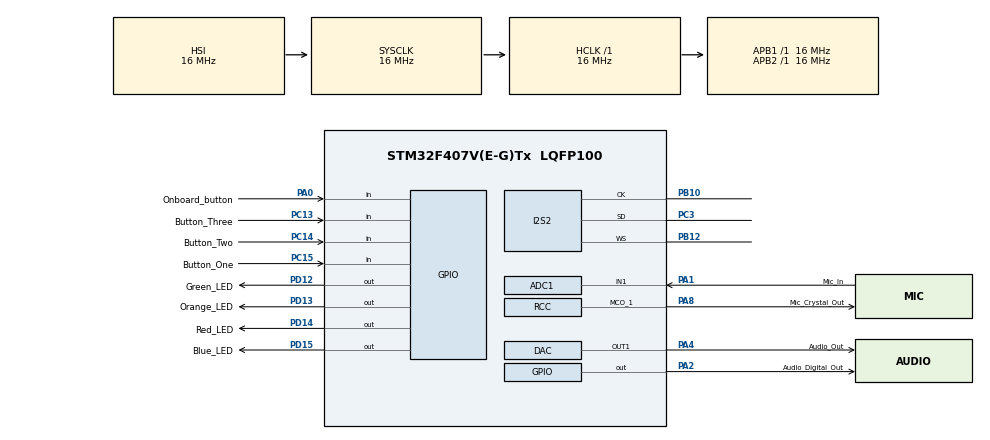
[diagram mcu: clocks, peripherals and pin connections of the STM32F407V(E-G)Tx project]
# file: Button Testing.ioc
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ADC1.Channel-0\#ChannelRegularConversion=ADC_CHANNEL_1
ADC1.NbrOfConversionFlag=1
ADC1.Rank-0\#ChannelRegularConversion=1
ADC1.SamplingTime-0\#ChannelRegularConversion=ADC_SAMPLETIME_3CYCLES
ADC1.master=1
I2S2.ErrorAudioFreq=0.0 %
I2S2.FullDuplexMode=I2S_FULLDUPLEXMODE_DISABLE
I2S2.Instance=SPI$Index
I2S2.RealAudioFreq=8.0 KHz
I2S2.VirtualMode=I2S_MODE_MASTER
Mcu.Family=STM32F4
Mcu.Name=STM32F407V(E-G)Tx
Mcu.Package=LQFP100
NVIC.PriorityGroup=NVIC_PRIORITYGROUP_4
PA0-WKUP.GPIO_Label=Onboard_button
PA0-WKUP.Signal=GPIO_Input
PA1.GPIO_Label=Mic_In
PA1.Signal=ADCx_IN1
PA2.GPIO_Label=Audio_Digital_Out
PA2.Signal=GPIO_Output
PA4.GPIO_Label=Audio_Out
PA4.Signal=COMP_DAC1_group
PA8.GPIO_Label=Mic_Crystal_Out
PA8.Mode=Clock-out-1
PA8.Signal=RCC_MCO_1
PB10.Mode=Half_Duplex_Master
PB10.Signal=I2S2_CK
PB12.Mode=Half_Duplex_Master
PB12.Signal=I2S2_WS
PC13-ANTI_TAMP.GPIO_Label=Button_Three
PC13-ANTI_TAMP.GPIO_PuPd=GPIO_PULLDOWN
PC13-ANTI_TAMP.Signal=GPIO_Input
PC14-OSC32_IN.GPIO_Label=Button_Two
PC14-OSC32_IN.GPIO_PuPd=GPIO_PULLDOWN
PC14-OSC32_IN.Signal=GPIO_Input
PC15-OSC32_OUT.GPIO_Label=Button_One
PC15-OSC32_OUT.GPIO_PuPd=GPIO_PULLDOWN
PC15-OSC32_OUT.Signal=GPIO_Input
PC3.Mode=Half_Duplex_Master
PC3.Signal=I2S2_SD
PD12.GPIO_Label=Green_LED
PD12.Signal=GPIO_Output
PD13.GPIO_Label=Orange_LED
PD13.Signal=GPIO_Output
PD14.GPIO_Label=Red_LED
PD14.Signal=GPIO_Output
PD15.GPIO_Label=Blue_LED
PD15.Signal=GPIO_Output
PH0-OSC_IN.Mode=HSE-External-Oscillator
PH0-OSC_IN.Signal=RCC_OSC_IN
PH1-OSC_OUT.Mode=HSE-External-Oscillator
PH1-OSC_OUT.Signal=RCC_OSC_OUT
ProjectManager.HeapSize=0x200
ProjectManager.StackSize=0x400
ProjectManager.TargetToolchain=STM32CubeIDE
RCC.AHBFreq_Value=16000000
RCC.APB1Freq_Value=16000000
RCC.APB2Freq_Value=16000000
RCC.CortexFreq_Value=16000000
RCC.HSE_VALUE=25000000
RCC.HSI_VALUE=16000000
RCC.LSE_VALUE=32768
RCC.RCC_MCODiv1=RCC_MCODIV_5
RCC.SYSCLKFreq_VALUE=16000000
RCC.VCOOutputFreq_Value=192000000
SH.ADCx_IN1.0=ADC1_IN1,IN1
SH.COMP_DAC1_group.0=DAC_OUT1,DAC_OUT1
board=custom

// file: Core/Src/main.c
/* USER CODE BEGIN Header */
/**
  ******************************************************************************
  * @file           : main.c
  * @brief          : Main program body
  ******************************************************************************
  * @attention
  *
  * Copyright (c) 2024 STMicroelectronics.
  * All rights reserved.
  *
  * This software is licensed under terms that can be found in the LICENSE file
  * in the root directory of this software component.
  * If no LICENSE file comes with this software, it is provided AS-IS.
  *
  ******************************************************************************
  */
/* USER CODE END Header */
#include "main.h"

/* USER CODE BEGIN Includes */
#include <stdio.h>

/* USER CODE END Includes */

ADC_HandleTypeDef hadc1;

DAC_HandleTypeDef hdac;

I2S_HandleTypeDef hi2s2;

void SystemClock_Config(void);
static void MX_GPIO_Init(void);
static void MX_ADC1_Init(void);
static void MX_DAC_Init(void);
static void MX_I2S2_Init(void);

int main(void)
{

  /* MCU Configuration--------------------------------------------------------*/

  /* Reset of all peripherals, Initializes the Flash interface and the Systick. */
  HAL_Init();

  /* Configure the system clock */
  SystemClock_Config();

  /* Initialize all configured peripherals */
  MX_GPIO_Init();
  MX_ADC1_Init();
  MX_DAC_Init();
  MX_I2S2_Init();
  /* USER CODE BEGIN 2 */

  HAL_DAC_Start(&hdac, DAC_CHANNEL_1);

  /* USER CODE END 2 */

  /* Infinite loop */
  /* USER CODE BEGIN WHILE */
//  int cycleLength = 500;
//  int cycleCount = 0;
//  int val = 0;
//  uint32_t var;
  uint16_t data[2];
  while (1)
  {
    /* USER CODE END WHILE */

    /* USER CODE BEGIN 3 */
//	  uint8_t onboard_button_val = HAL_GPIO_ReadPin(Onboard_button_GPIO_Port, Onboard_button_Pin);
//	  uint8_t button_one_val = HAL_GPIO_ReadPin(Button_One_GPIO_Port, Button_One_Pin);
//	  uint8_t button_two_button_val = HAL_GPIO_ReadPin(Button_Two_GPIO_Port, Button_Two_Pin);
//	  uint8_t button_three_button_val = HAL_GPIO_ReadPin(Button_Three_GPIO_Port, Button_Three_Pin);
//
//	  HAL_GPIO_WritePin(Green_LED_GPIO_Port, Green_LED_Pin, onboard_button_val);
//	  HAL_GPIO_WritePin(Orange_LED_GPIO_Port, Orange_LED_Pin, button_one_val);
//	  HAL_GPIO_WritePin(Red_LED_GPIO_Port, Red_LED_Pin, button_two_button_val);
//	  HAL_GPIO_WritePin(Blue_LED_GPIO_Port, Blue_LED_Pin, button_three_button_val);
//
//	  // Get ADC value
//	  HAL_ADC_Start(&hadc1);
//	  HAL_ADC_PollForConversion(&hadc1, HAL_MAX_DELAY);
//	  uint16_t raw = HAL_ADC_GetValue(&hadc1);

	  HAL_I2S_Receive(&hi2s2, &data, 1, 10);

//	  if (cycleCount >= cycleLength) {
//		  val = val == 0 ? 4096 : 0;
//		  cycleCount = 0;
//	  }

//	  cycleCount++;

	  HAL_DAC_SetValue(&hdac, DAC_CHANNEL_1, DAC_ALIGN_12B_R, data);
  }
  /* USER CODE END 3 */
}

void SystemClock_Config(void)
{
  RCC_OscInitTypeDef RCC_OscInitStruct = {0};
  RCC_ClkInitTypeDef RCC_ClkInitStruct = {0};

  /** Macro to configure the PLL multiplication factor
  */
  __HAL_RCC_PLL_PLLM_CONFIG(16);

  /** Macro to configure the PLL clock source
  */
  __HAL_RCC_PLL_PLLSOURCE_CONFIG(RCC_PLLSOURCE_HSI);

  /** Configure the main internal regulator output voltage
  */
  __HAL_RCC_PWR_CLK_ENABLE();
  __HAL_PWR_VOLTAGESCALING_CONFIG(PWR_REGULATOR_VOLTAGE_SCALE1);

  /** Initializes the RCC Oscillators according to the specified parameters
  * in the RCC_OscInitTypeDef structure.
  */
  RCC_OscInitStruct.OscillatorType = RCC_OSCILLATORTYPE_HSI;
  RCC_OscInitStruct.HSIState = RCC_HSI_ON;
  RCC_OscInitStruct.HSICalibrationValue = RCC_HSICALIBRATION_DEFAULT;
  RCC_OscInitStruct.PLL.PLLState = RCC_PLL_NONE;
  RCC_OscInitStruct.PLL.PLLSource = RCC_PLLSOURCE_HSI;
  if (HAL_RCC_OscConfig(&RCC_OscInitStruct) != HAL_OK)
  {
    Error_Handler();
  }

  /** Initializes the CPU, AHB and APB buses clocks
  */
  RCC_ClkInitStruct.ClockType = RCC_CLOCKTYPE_HCLK|RCC_CLOCKTYPE_SYSCLK
                              |RCC_CLOCKTYPE_PCLK1|RCC_CLOCKTYPE_PCLK2;
  RCC_ClkInitStruct.SYSCLKSource = RCC_SYSCLKSOURCE_HSI;
  RCC_ClkInitStruct.AHBCLKDivider = RCC_SYSCLK_DIV1;
  RCC_ClkInitStruct.APB1CLKDivider = RCC_HCLK_DIV1;
  RCC_ClkInitStruct.APB2CLKDivider = RCC_HCLK_DIV1;

  if (HAL_RCC_ClockConfig(&RCC_ClkInitStruct, FLASH_LATENCY_0) != HAL_OK)
  {
    Error_Handler();
  }
  HAL_RCC_MCOConfig(RCC_MCO1, RCC_MCO1SOURCE_HSI, RCC_MCODIV_5);
}

static void MX_ADC1_Init(void)
{

  ADC_ChannelConfTypeDef sConfig = {0};

  /** Configure the global features of the ADC (Clock, Resolution, Data Alignment and number of conversion)
  */
  hadc1.Instance = ADC1;
  hadc1.Init.ClockPrescaler = ADC_CLOCK_SYNC_PCLK_DIV2;
  hadc1.Init.Resolution = ADC_RESOLUTION_12B;
  hadc1.Init.ScanConvMode = DISABLE;
  hadc1.Init.ContinuousConvMode = DISABLE;
  hadc1.Init.DiscontinuousConvMode = DISABLE;
  hadc1.Init.ExternalTrigConvEdge = ADC_EXTERNALTRIGCONVEDGE_NONE;
  hadc1.Init.ExternalTrigConv = ADC_SOFTWARE_START;
  hadc1.Init.DataAlign = ADC_DATAALIGN_RIGHT;
  hadc1.Init.NbrOfConversion = 1;
  hadc1.Init.DMAContinuousRequests = DISABLE;
  hadc1.Init.EOCSelection = ADC_EOC_SINGLE_CONV;
  if (HAL_ADC_Init(&hadc1) != HAL_OK)
  {
    Error_Handler();
  }

  /** Configure for the selected ADC regular channel its corresponding rank in the sequencer and its sample time.
  */
  sConfig.Channel = ADC_CHANNEL_1;
  sConfig.Rank = 1;
  sConfig.SamplingTime = ADC_SAMPLETIME_3CYCLES;
  if (HAL_ADC_ConfigChannel(&hadc1, &sConfig) != HAL_OK)
  {
    Error_Handler();
  }

}

static void MX_DAC_Init(void)
{

  DAC_ChannelConfTypeDef sConfig = {0};

  /** DAC Initialization
  */
  hdac.Instance = DAC;
  if (HAL_DAC_Init(&hdac) != HAL_OK)
  {
    Error_Handler();
  }

  /** DAC channel OUT1 config
  */
  sConfig.DAC_Trigger = DAC_TRIGGER_NONE;
  sConfig.DAC_OutputBuffer = DAC_OUTPUTBUFFER_ENABLE;
  if (HAL_DAC_ConfigChannel(&hdac, &sConfig, DAC_CHANNEL_1) != HAL_OK)
  {
    Error_Handler();
  }

}

static void MX_I2S2_Init(void)
{

  hi2s2.Instance = SPI2;
  hi2s2.Init.Mode = I2S_MODE_MASTER_TX;
  hi2s2.Init.Standard = I2S_STANDARD_PHILIPS;
  hi2s2.Init.DataFormat = I2S_DATAFORMAT_16B;
  hi2s2.Init.MCLKOutput = I2S_MCLKOUTPUT_DISABLE;
  hi2s2.Init.AudioFreq = I2S_AUDIOFREQ_8K;
  hi2s2.Init.CPOL = I2S_CPOL_LOW;
  hi2s2.Init.ClockSource = I2S_CLOCK_PLL;
  hi2s2.Init.FullDuplexMode = I2S_FULLDUPLEXMODE_DISABLE;
  if (HAL_I2S_Init(&hi2s2) != HAL_OK)
  {
    Error_Handler();
  }

}

static void MX_GPIO_Init(void)
{
  GPIO_InitTypeDef GPIO_InitStruct = {0};

  /* GPIO Ports Clock Enable */
  __HAL_RCC_GPIOC_CLK_ENABLE();
  __HAL_RCC_GPIOH_CLK_ENABLE();
  __HAL_RCC_GPIOA_CLK_ENABLE();
  __HAL_RCC_GPIOB_CLK_ENABLE();
  __HAL_RCC_GPIOD_CLK_ENABLE();

  /*Configure GPIO pin Output Level */
  HAL_GPIO_WritePin(Audio_Digital_Out_GPIO_Port, Audio_Digital_Out_Pin, GPIO_PIN_RESET);

  /*Configure GPIO pin Output Level */
  HAL_GPIO_WritePin(GPIOD, Green_LED_Pin|Orange_LED_Pin|Red_LED_Pin|Blue_LED_Pin, GPIO_PIN_RESET);

  /*Configure GPIO pins : Button_Three_Pin Button_Two_Pin Button_One_Pin */
  GPIO_InitStruct.Pin = Button_Three_Pin|Button_Two_Pin|Button_One_Pin;
  GPIO_InitStruct.Mode = GPIO_MODE_INPUT;
  GPIO_InitStruct.Pull = GPIO_PULLDOWN;
  HAL_GPIO_Init(GPIOC, &GPIO_InitStruct);

  /*Configure GPIO pin : Onboard_button_Pin */
  GPIO_InitStruct.Pin = Onboard_button_Pin;
  GPIO_InitStruct.Mode = GPIO_MODE_INPUT;
  GPIO_InitStruct.Pull = GPIO_NOPULL;
  HAL_GPIO_Init(Onboard_button_GPIO_Port, &GPIO_InitStruct);

  /*Configure GPIO pin : Audio_Digital_Out_Pin */
  GPIO_InitStruct.Pin = Audio_Digital_Out_Pin;
  GPIO_InitStruct.Mode = GPIO_MODE_OUTPUT_PP;
  GPIO_InitStruct.Pull = GPIO_NOPULL;
  GPIO_InitStruct.Speed = GPIO_SPEED_FREQ_LOW;
  HAL_GPIO_Init(Audio_Digital_Out_GPIO_Port, &GPIO_InitStruct);

  /*Configure GPIO pins : Green_LED_Pin Orange_LED_Pin Red_LED_Pin Blue_LED_Pin */
  GPIO_InitStruct.Pin = Green_LED_Pin|Orange_LED_Pin|Red_LED_Pin|Blue_LED_Pin;
  GPIO_InitStruct.Mode = GPIO_MODE_OUTPUT_PP;
  GPIO_InitStruct.Pull = GPIO_NOPULL;
  GPIO_InitStruct.Speed = GPIO_SPEED_FREQ_LOW;
  HAL_GPIO_Init(GPIOD, &GPIO_InitStruct);

  /*Configure GPIO pin : Mic_Crystal_Out_Pin */
  GPIO_InitStruct.Pin = Mic_Crystal_Out_Pin;
  GPIO_InitStruct.Mode = GPIO_MODE_AF_PP;
  GPIO_InitStruct.Pull = GPIO_NOPULL;
  GPIO_InitStruct.Speed = GPIO_SPEED_FREQ_LOW;
  GPIO_InitStruct.Alternate = GPIO_AF0_MCO;
  HAL_GPIO_Init(Mic_Crystal_Out_GPIO_Port, &GPIO_InitStruct);

}

/* USER CODE BEGIN 4 */
int _write(int file, char *ptr, int len)
{
  (void)file;
  int DataIdx;

  for (DataIdx = 0; DataIdx < len; DataIdx++)
  {
    ITM_SendChar(*ptr++);
  }
  return len;
}

/* USER CODE END 4 */

void Error_Handler(void)
{
  __disable_irq();
  while (1)
  {
  }
}
